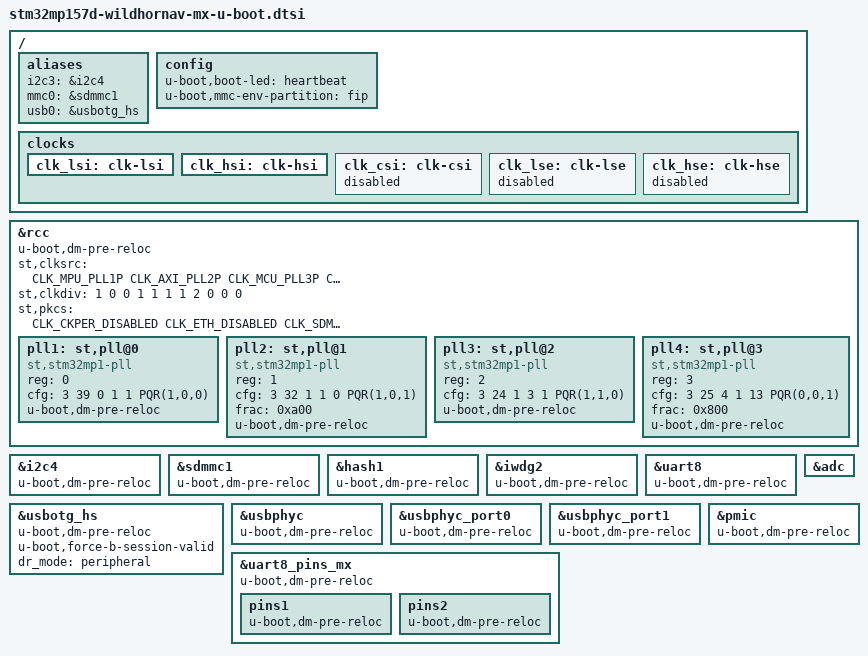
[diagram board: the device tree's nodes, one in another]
/* SPDX-License-Identifier: GPL-2.0+ OR BSD-3-Clause*/
/*
 * Copyright (C) 2022, STMicroelectronics - All Rights Reserved
 * Author: STM32CubeMX code generation for STMicroelectronics.
 */

/* For more information on Device Tree configuration, please refer to
 * https://wiki.st.com/stm32mpu/wiki/Category:Device_tree_configuration
 */

#include <dt-bindings/clock/stm32mp1-clksrc.h>
#include "stm32mp15-mx.dtsi"

#include "stm32mp15-u-boot.dtsi"
#include "stm32mp15-ddr.dtsi"

/* USER CODE BEGIN includes */
/* USER CODE END includes */

/ {

	/* USER CODE BEGIN root */
	
	aliases{
		i2c3 = &i2c4;
		mmc0 = &sdmmc1;
		usb0 = &usbotg_hs;
	};

	config{
		u-boot,boot-led = "heartbeat";
		//u-boot,error-led = "error";
		u-boot,mmc-env-partition = "fip";
		//st,adc_usb_pd = <&adc1 18>, <&adc1 19>;
		//st,fastboot-gpios = <&gpioa 13 GPIO_ACTIVE_LOW>;
		//st,stm32prog-gpios = <&gpioa 14 GPIO_ACTIVE_LOW>;
	};
	
	/* USER CODE END root */

	clocks {
		/* USER CODE BEGIN clocks */
		/* USER CODE END clocks */

#ifndef CONFIG_TFABOOT
		clk_lsi: clk-lsi {

			/* USER CODE BEGIN clk_lsi */
			/* USER CODE END clk_lsi */
		};
		clk_hsi: clk-hsi {

			/* USER CODE BEGIN clk_hsi */
			/* USER CODE END clk_hsi */
		};
		clk_csi: clk-csi {
			status = "disabled";

			/* USER CODE BEGIN clk_csi */
			/* USER CODE END clk_csi */
		};
		clk_lse: clk-lse {
			status = "disabled";

			/* USER CODE BEGIN clk_lse */
			/* USER CODE END clk_lse */
		};
		clk_hse: clk-hse {
			status = "disabled";

			/* USER CODE BEGIN clk_hse */
			/* USER CODE END clk_hse */
		};
#endif	/*CONFIG_TFABOOT*/
	};

}; /*root*/

#ifndef CONFIG_TFABOOT

&rcc{
	u-boot,dm-pre-reloc;
	st,clksrc = <
		CLK_MPU_PLL1P
		CLK_AXI_PLL2P
		CLK_MCU_PLL3P
		CLK_PLL12_HSI
		CLK_PLL3_HSI
		CLK_PLL4_HSI
		CLK_RTC_LSI
		CLK_MCO1_DISABLED
		CLK_MCO2_DISABLED
	>;
	st,clkdiv = <
		1 		/*MPU*/
		0 		/*AXI*/
		0 		/*MCU*/
		1 		/*APB1*/
		1 		/*APB2*/
		1 		/*APB3*/
		1 		/*APB4*/
		2 		/*APB5*/
		0 		/*RTC*/
		0 		/*MCO1*/
		0 		/*MCO2*/
	>;
	st,pkcs = <
		CLK_CKPER_DISABLED
		CLK_ETH_DISABLED
		CLK_SDMMC12_HSI
		CLK_STGEN_HSI
		CLK_USBPHY_PLL4R
		CLK_SPI2S1_DISABLED
		CLK_SPI2S23_DISABLED
		CLK_SPI45_DISABLED
		CLK_SPI6_DISABLED
		CLK_I2C46_HSI
		CLK_SDMMC3_DISABLED
		CLK_USBO_USBPHY
		CLK_ADC_PLL3Q
		CLK_CEC_DISABLED
		CLK_I2C12_PCLK1
		CLK_I2C35_PCLK1
		CLK_UART1_DISABLED
		CLK_UART24_PCLK1
		CLK_UART35_PCLK1
		CLK_UART6_PCLK2
		CLK_UART78_HSI
		CLK_SPDIF_DISABLED
		CLK_FDCAN_PLL3Q
		CLK_SAI1_DISABLED
		CLK_SAI2_DISABLED
		CLK_SAI3_DISABLED
		CLK_SAI4_DISABLED
		CLK_LPTIM1_DISABLED
		CLK_LPTIM23_DISABLED
		CLK_LPTIM45_DISABLED
	>;
	pll1:st,pll@0 {
		compatible = "st,stm32mp1-pll";
		reg = <0>;
		cfg = < 3 39 0 1 1 PQR(1,0,0) >;
		u-boot,dm-pre-reloc;
	};
	pll2:st,pll@1 {
		compatible = "st,stm32mp1-pll";
		reg = <1>;
		cfg = < 3 32 1 1 0 PQR(1,0,1) >;
		frac = < 0xa00 >;
		u-boot,dm-pre-reloc;
	};
	pll3:st,pll@2 {
		compatible = "st,stm32mp1-pll";
		reg = <2>;
		cfg = < 3 24 1 3 1 PQR(1,1,0) >;
		u-boot,dm-pre-reloc;
	};
	pll4:st,pll@3 {
		compatible = "st,stm32mp1-pll";
		reg = <3>;
		cfg = < 3 25 4 1 13 PQR(0,0,1) >;
		frac = < 0x800 >;
		u-boot,dm-pre-reloc;
	};

	/* USER CODE BEGIN rcc */
	/* USER CODE END rcc */
};

&i2c4{
	u-boot,dm-pre-reloc;

	/* USER CODE BEGIN i2c4 */
	/* USER CODE END i2c4 */
};

&sdmmc1{
	u-boot,dm-pre-reloc;

	/* USER CODE BEGIN sdmmc1 */
	/* USER CODE END sdmmc1 */
};

#endif	/*CONFIG_TFABOOT*/

&hash1{
	u-boot,dm-pre-reloc;

	/* USER CODE BEGIN hash1 */
	/* USER CODE END hash1 */
};

&iwdg2{
	u-boot,dm-pre-reloc;

	/* USER CODE BEGIN iwdg2 */
	/* USER CODE END iwdg2 */
};

&uart8{
	u-boot,dm-pre-reloc;

	/* USER CODE BEGIN uart8 */
	/* USER CODE END uart8 */
};

&usbotg_hs{
	u-boot,dm-pre-reloc;

	/* USER CODE BEGIN usbotg_hs */
	
	u-boot,force-b-session-valid;
	dr_mode = "peripheral";
	
	/* USER CODE END usbotg_hs */
};

&usbphyc{
	u-boot,dm-pre-reloc;

	/* USER CODE BEGIN usbphyc */
	/* USER CODE END usbphyc */
};

&usbphyc_port0{
	u-boot,dm-pre-reloc;

	/* USER CODE BEGIN usbphyc_port0 */
	/* USER CODE END usbphyc_port0 */
};

&usbphyc_port1{
	u-boot,dm-pre-reloc;

	/* USER CODE BEGIN usbphyc_port1 */
	/* USER CODE END usbphyc_port1 */
};

/* USER CODE BEGIN addons */

&adc{
	status = "okay";
};


#ifndef CONFIG_TFABOOT

&pmic{
	u-boot,dm-pre-reloc;
};

#endif /*CONFIG_TFABOOT*/

&uart8_pins_mx{
	u-boot,dm-pre-reloc;
	pins1 {
		u-boot,dm-pre-reloc;
	};
	pins2 {
		u-boot,dm-pre-reloc;
	};
};

/* USER CODE END addons */

